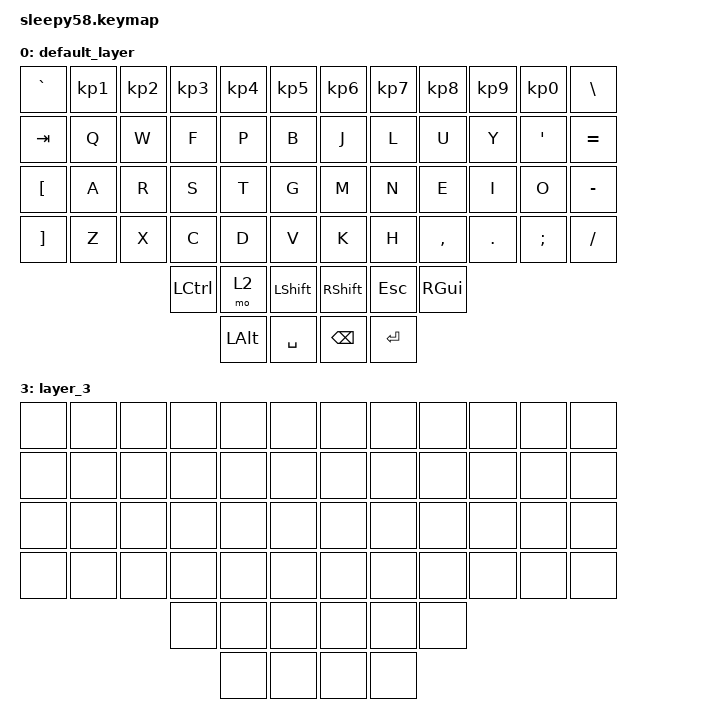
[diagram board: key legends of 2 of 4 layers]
#include <behaviors.dtsi>
#include <dt-bindings/zmk/keys.h>

/ {
    keymap {
        compatible = "zmk,keymap";

        default_layer { // Base layer
            bindings = <
                &kp GRAVE   &kp KP_N1      &kp KP_N2      &kp KP_N3      &kp KP_N4      &kp KP_N5      &kp KP_N6      &kp KP_N7      &kp KP_N8      &kp KP_N9      &kp KP_N0      &kp BSLH
                &kp TAB     &kp Q       &kp W       &kp F       &kp P       &kp B       &kp J       &kp L       &kp U       &kp Y       &kp QUOT    &kp EQUAL
                &kp LBKT    &kp A       &kp R       &kp S       &kp T       &kp G       &kp M       &kp N       &kp E       &kp I       &kp O       &kp MINUS
                &kp RBKT    &kp Z       &kp X       &kp C       &kp D       &kp V       &kp K       &kp H       &kp COMMA   &kp DOT     &kp SCLN    &kp FSLH
                                                &kp LCTRL   &mo 2       &kp LSHFT       &kp RSHFT      &kp ESC       &kp RGUI 
                                                            &kp LALT    &kp SPACE       &kp BSPC     &kp ENTER
            >;
        };
        
        layer_1 { // Qwerty layer
            bindings = <
                &kp GRAVE   &kp KP_N1      &kp KP_N2      &kp KP_N3      &kp KP_N4      &kp KP_N5      &kp KP_N6      &kp KP_N7      &kp KP_N8      &kp KP_N9      &kp KP_N0      &kp BSLH
                &kp TAB     &kp Q       &kp W       &kp E       &kp R       &kp T       &kp Y       &kp U       &kp I       &kp O       &kp P       &kp EQUAL
                &kp LBKT    &kp A       &kp S       &kp D       &kp F       &kp G       &kp H       &kp J       &kp K       &kp L       &kp QUOT    &kp RBKT
                                                &kp LCTRL   &mo 2       &kp LSHFT       &kp RSHFT      &kp ESC       &kp RGUI 
                                                            &kp LALT    &kp SPACE       &kp BSPC     &kp ENTER
            >;
        };
        
        layer_2 { // Function and Media Keys layer
            bindings = <
                &kp CAPS       &kp F1      &kp F2      &kp F3      &kp F4      &kp F5      &kp F6      &kp F7      &kp F8      &kp F9      &kp F10     &kp F11
                &kp C_NEXT       &kp C_PLAY_PAUSE     &kp C_VOL_UP &kp C_VOL_DN     &kp PG_UP    &kp HOME    &none   &none    &kp PSCRN    &kp PAUS    &none      &kp F12
                &kp C_PREV      &kp LEFT    &kp DOWN    &kp UP      &kp RIGHT   &kp DEL     &none        &kp RA(Q)   &kp RA(W)   &kp RA(E)   &none      &none
                                                &kp LCTRL   &mo 2       &kp LSHFT       &kp RSHFT      &kp ESC       &kp RGUI 
                                                            &kp LALT    &kp SPACE       &kp BSPC     &kp ENTER
            >;
        };
        
        layer_3 { // Empty layer
            bindings = <
                &none    &none    &none    &none    &none    &none    &none    &none    &none    &none    &none    &none    
                &none    &none    &none    &none    &none    &none    &none    &none    &none    &none    &none    &none    
                &none    &none    &none    &none    &none    &none    &none    &none    &none    &none    &none    &none    
                &none    &none    &none    &none    &none    &none    &none    &none    &none    &none    &none    &none    
                                           &none    &none    &none    &none    &none    &none    
                                                    &none    &none    &none    &none    
            >;
        };
    };
};
